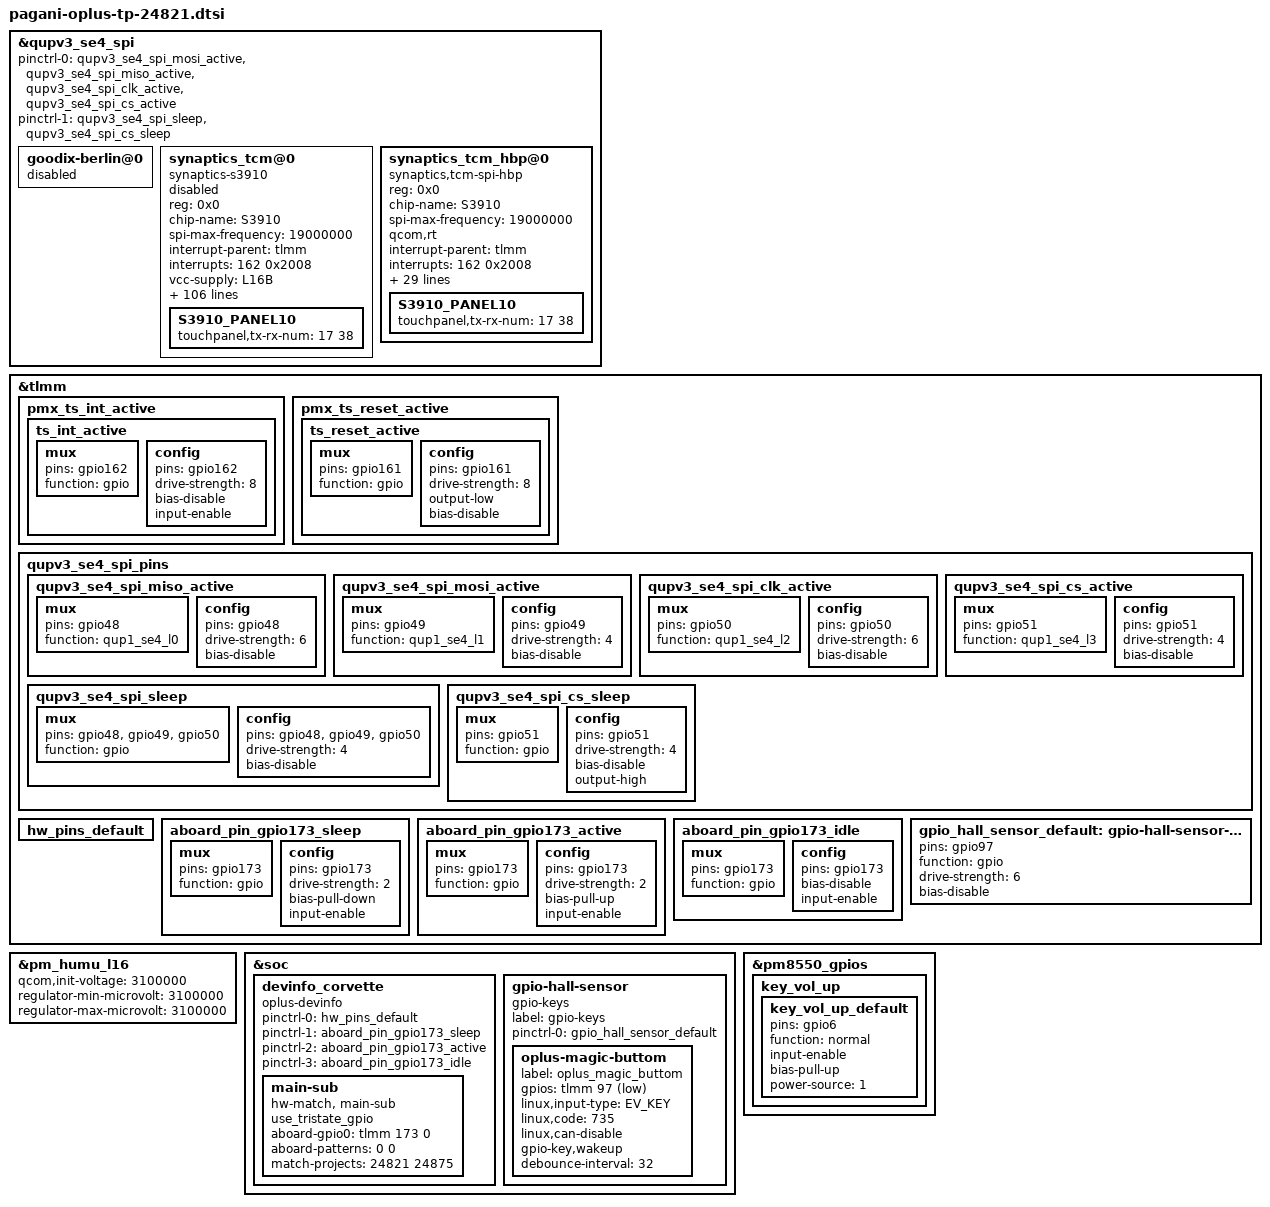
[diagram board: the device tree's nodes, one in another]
&qupv3_se4_spi{
	/delete-property/ pinctrl-0;
	/delete-property/ pinctrl-1;
	pinctrl-0 = <&qupv3_se4_spi_mosi_active>, <&qupv3_se4_spi_miso_active>,
				<&qupv3_se4_spi_clk_active>, <&qupv3_se4_spi_cs_active>;
	pinctrl-1 = <&qupv3_se4_spi_sleep>, <&qupv3_se4_spi_cs_sleep>;
};

&qupv3_se4_spi {
	status = "ok";

	goodix-berlin@0 {
		status = "disabled";
	};

	synaptics_tcm@0{
		compatible = "synaptics-s3910";
		reg = <0x0>;
		chip-name = "S3910";
		status = "disabled";
		spi-max-frequency = <19000000>;

		/* Interrupt && Irq-gpio */
		interrupt-parent = <&tlmm>;
		interrupts = <162 0x2008>;

		/* Power Config */
		//synaptics,avdd-gpio = <&pm8550vs_j_gpios 3 0x1>;
		vcc-supply = <&L16B>;
		vdd-supply = <&L4B>;
		synaptics,vdd-name = "vdd";
		synaptics,avdd-name = "vcc";

		/* Other HW Resource */
		irq-gpio = <&tlmm 162 0x2008>;
		reset-gpio = <&tlmm 161 0x1>;
		pinctrl-names = "default";
		pinctrl-0 = <&ts_int_active &ts_reset_active>;


		touchpanel,max-num-support = <10>;
		touchpanel,tx-rx-num = <17 37>;
		touchpanel,panel-coords = <19456 42240>;
		touchpanel,display-coords = <1216 2640>;
		touchpanel,touchmajor-limit = <128 216>;
		touchpanel,elimination-range = <20 200 200>;
		touchpanel,int-mode = <1>; /*0: interrupt and disable, 1:interrupt and not disable*/
		touchpanel,smooth-level = <0 1 2 4 7 9>;
		touchpanel,smooth-level-charging = <0 2 4 7 8 9>;
		touchpanel,sensitive-level = <0 70 55 40 25 10>;
		touchpanel,single-optimized-time = <8>;
		touchpanel,high-frame-rate-time = <60>;

		vid_len = <2>;
		panel_type = <7>; /*type:3 TM*/
		platform_support_project = <24821>;
		platform_support_project_dir = <24821>;
		platform_support_project_commandline = "default_commandline";

		prevention,curved_screen_V2;
		prevention,grip_disable_level = <6>;
		prevention,updelay_time_ms = <30>;
		prevention,makeup_cnt_weight = <4 1 2 2 2>;
		prevention,large_corner_range = <1380 3400>;
		prevention,large_corner_judge_condition = <500 300 1000 7 7>;
		prevention,trx_reject_condition = <8 7 7>;
		prevention,trx_strict_reject_condition = <8 6 6>;
		prevention,large_judge_time_ms = <500 50 30>;
		prevention,large_exit_condition = <8 8 2>;
		prevention,single_channel_width = <320 320>;
		prevention,normal_tap_condition = <10 350>;
		prevention,long_edge_condition = <179 90 120 80>;
		prevention,long_strict_edge_condition = <160 60>;
		prevention,long_fingerhold_condition = <70 6 4 4>;
		prevention,short_edge_condition = <179 90 120 80>;
		prevention,short_strict_edge_condition = <160 60>;
		prevention,large_strict_exit_condition = <6 6>;
		prevention,top_corner_config = <250 750 1000>;
		prevention,edge_swipe_config = <340 1130>;

		prevention,curved_screen_V4;
		prevention,long_eliminate_point_type = <2 12400 9240 240 27720 300 1>;
		prevention,long_fingerhold_condition2 = <700 2000 0 0>;
		prevention,top_corner_config2 =<3 80 600 1500 0>;
		prevention,hor_long_top_corner_config =<300 2000 0 0>;
		prevention,top_middle_config =<12400 1000 1000 0>;
		prevention,corner_eliminate_point_type =<0 1380 2270 1>;
		prevention,finger_hold_differ_size = <1 0 400 300>;
		prevention,finger_hold_max_rx_exit_distance = <5 350 2300>;
		prevention,max_rx_exit_distance = <1 5 150 350 2000>;
		prevention,dynamic_finger_hold_exit_distance = <1 350 2300 450>;
		prevention,edge_sliding_matched_support = <1 150 3 0>;

		//grip v4.2 reclining mode
		prevention,reclining_mode_support = <1>;
		prevention,long_eliminate_point_type_recli = <2 12400 9240 240 27720 500 1>;
		prevention,finger_hold_differ_size_recli = <1 0 400 400>;
		prevention,finger_hold_max_rx_exit_distance_recli = <5 350 2300>;
		prevention,max_rx_exit_distance_recli = <1 5 100 350 2300>;
		prevention,dynamic_finger_hold_exit_distance_recli = <1 350 2300 450>;
		prevention,edge_sliding_matched_support_recli = <1 150 3 0>;
		prevention,long_edge_condition_recli = <179 90 120 80>;


		/* SW Support Feature Control */
		black_gesture_support;
		sportify_aod_gesture_support;
		pressure_report_support;
		charger_pump_support;
		game_switch_support;
		glove_mode_support;
		smart_gesture_support;
		fw_update_app_support;
		fingerprint_underscreen_support;
		freq_hop_simulate_support;
		report_flow_unlock_support;
		screenoff_fingerprint_info_support;
		irq_need_dev_resume_ok;
		enable_point_auto_change;
		kernel_grip_support;
		//grip_no_driver_support;
		health_monitor_support;
		black_gesture_indep_support;
		snr_read_support;
		palm_to_sleep_support;
		exception_upload_support;
		tp_data_record_support;
		fingerprint_not_report_in_suspend;
		/*
		 *Virtual Key Config:
		 *1:touchpanel,button-type: <virtualkey_type  supportted_button-map>
		 *virtualkey_type:
		 *Type 1: using board_properties
		 *Type 2: using same IC (button zone&& touch zone are seprate)
		 *Type 3: using diffrent IC (button zone&& touch zone are seprate)
		 *Type 4: No need of virtual key process
		 *supportted_button-map:select|menu|home|back
		 *
		 *2:touchpanel,button-map
		 *type (X1,Y1)(X2,Y2)(X3,Y3)(Width_X,Hight_Y)--Only when button-type is 0
		 */
		touchpanel,button-type = <4>;
		touchpanel.button-TRx = <0 0>;

		S3910_PANEL10 {
			touchpanel,tx-rx-num = <17 38>;
		};
	};

	synaptics_tcm_hbp@0{
		compatible = "synaptics,tcm-spi-hbp";
		reg = <0x0>;
		chip-name = "S3910";
		status = "okay";
		spi-max-frequency = <19000000>;
		qcom,rt;

		/* Interrupt && Irq-gpio */
		interrupt-parent = <&tlmm>;
		interrupts = <162 0x2008>;

		/* Power Config */
		//synaptics,avdd-gpio = <&pm8550vs_j_gpios 3 0x1>;
		vcc-supply = <&L16B>;
		vdd-supply = <&L4B>;
		synaptics,vdd-name = "vdd";
		synaptics,avdd-name = "vcc";

		/* Other HW Resource */
		synaptics,irq-gpio = <&tlmm 162 0x2008>;
		synaptics,reset-gpio = <&tlmm 161 0x1>;
		pinctrl-names = "default";
		pinctrl-0 = <&ts_int_active &ts_reset_active>;

		touchpanel,panel-coords = <19456 42240>;
		touchpanel,tx-rx-num = <17 37>;
		touchpanel,tp_ic_type = <2>;
		panel_type = <10 7>;
		// type of tp_dev ,TP-SAMSUNG = 8;
		firmware_name = "AA590";
		platform_support_project = <24821 24875>;
		platform_support_project_dir = <24821 24821>;
		platform_support_project_commandline = "mdss_dsi_panel_AA590_P_3_A0020_dsc_cmd", "mdss_dsi_panel_AA594_P_7_A0020_dsc_cmd";

		synaptics,power-on-state = <1>;
		synaptics,power-delay-ms = <200>;
		synaptics,irq-on-state = <0>;
		synaptics,reset-on-state = <0>;
		synaptics,reset-active-ms = <10>;
		synaptics,reset-delay-ms = <80>;
		synaptics,spi-mode = <0>;
		synaptics,spi-byte-delay-us = <0>;
		synaptics,spi-block-delay-us = <0>;

		/* SW Support Feature Control */
		tp_data_record_support;
		stats_upload_support;
		fingerprint_not_report_in_suspend;
		S3910_PANEL10 {
			touchpanel,tx-rx-num = <17 38>;
		};
	};
};
/*
&pm8550vs_j_gpios {
	ts_avdd_active: ts_avdd_active {
		pins = "gpio3";
		function = "normal";
		input-disable;
		output-enable;
		output-low;
		power-source = <1>;
	};
};
*/
&tlmm {
/*	gpio_wakeup: gpio_wakeup {
		compatible = "gpio_wakeup";
		gpio_table = <8 11 15 20 23 56 57 59 63 65 66 77 81 84 153 155 171 172 177 188 195>;
	};
*/
	pmx_ts_int_active {
		ts_int_active: ts_int_active {
			mux {
				pins = "gpio162";
				function = "gpio";
			};

			config {
				pins = "gpio162";
				drive-strength = <8>;
				bias-disable;
				input-enable;
			};
		};
	};

	pmx_ts_reset_active {
		ts_reset_active: ts_reset_active {
			mux {
				pins = "gpio161";
				function = "gpio";
			};

			config {
				pins = "gpio161";
				drive-strength = <8>;
				output-low;
				bias-disable;
			};
		};
	};

	qupv3_se4_spi_pins: qupv3_se4_spi_pins {
		qupv3_se4_spi_miso_active: qupv3_se4_spi_miso_active {
			mux {
				pins = "gpio48";
				function = "qup1_se4_l0";
			};

			config {
				pins = "gpio48";
				drive-strength = <6>;
				bias-disable;
			};
		};

		qupv3_se4_spi_mosi_active: qupv3_se4_spi_mosi_active {
			mux {
				pins = "gpio49";
				function = "qup1_se4_l1";
			};

			config {
				pins = "gpio49";
				drive-strength = <4>;
				bias-disable;
			};
		};

		qupv3_se4_spi_clk_active: qupv3_se4_spi_clk_active {
			mux {
				pins = "gpio50";
				function = "qup1_se4_l2";
			};

			config {
				pins = "gpio50";
				drive-strength = <6>;
				bias-disable;
			};
		};

		qupv3_se4_spi_cs_active: qupv3_se4_spi_cs_active {
			mux {
				pins = "gpio51";
				function = "qup1_se4_l3";
			};

			config {
				pins = "gpio51";
				drive-strength = <4>;
				bias-disable;
			};
		};

		qupv3_se4_spi_sleep: qupv3_se4_spi_sleep {
			mux {
				pins = "gpio48", "gpio49",
						"gpio50";
				function = "gpio";
			};

			config {
				pins = "gpio48", "gpio49",
						"gpio50";
				drive-strength = <4>;
				bias-disable;
			};
		};

		qupv3_se4_spi_cs_sleep: qupv3_se4_spi_cs_sleep {
			mux {
				pins = "gpio51";
				function = "gpio";
			};

			config {
				pins = "gpio51";
				drive-strength = <4>;
				bias-disable;
				output-high;
			};
		};
	};

};

&pm_humu_l16 {
	qcom,init-voltage = <3100000>;
	regulator-min-microvolt = <3100000>;
	regulator-max-microvolt = <3100000>;
};

&soc {
	devinfo_corvette {
		compatible = "oplus-devinfo";
		pinctrl-names = "default", "sleep", "active", "idle";
		pinctrl-0 = <&hw_pins_default>;
		pinctrl-1 = <&aboard_pin_gpio173_sleep>;
		pinctrl-2 = <&aboard_pin_gpio173_active>;
		pinctrl-3 = <&aboard_pin_gpio173_idle>;

		main-sub {
			use_tristate_gpio;
			compatible = "hw-match, main-sub";
			aboard-gpio0 = <&tlmm 173 0>;
			aboard-patterns = <0 0>;	/*0[high-resistance] 1[pull-down] 2[pull-up]*/
			/*main board*/
			match-projects = <24821 24875>;
		};
	};
};

&tlmm {
	hw_pins_default:hw_pins_default {
	};
	aboard_pin_gpio173_sleep:aboard_pin_gpio173_sleep {
		mux {
			pins = "gpio173";
			function = "gpio";
		};
		config {
			pins = "gpio173";
			drive-strength = <2>;
			bias-pull-down;
			input-enable;
		};
	};

	aboard_pin_gpio173_active:aboard_pin_gpio173_active {
		mux {
			pins = "gpio173";
			function = "gpio";
		};
		config {
			pins = "gpio173";
			drive-strength = <2>;
			bias-pull-up;
			input-enable;
		};
	};

	aboard_pin_gpio173_idle:aboard_pin_gpio173_idle {
		mux {
			pins = "gpio173";
			function = "gpio";
		};
		config {
			pins = "gpio173";
			bias-disable;
			input-enable;
		};
	};
};

&pm8550_gpios {
	key_vol_up {
		key_vol_up_default: key_vol_up_default {
			pins = "gpio6";
			function = "normal";
			input-enable;
			bias-pull-up;
			power-source = <1>;
		};
	};
};

&soc {
	gpio-hall-sensor {
		compatible = "gpio-keys";
		label = "gpio-keys";
		status = "okay";
		pinctrl-0 = <&gpio_hall_sensor_default>;
		pinctrl-names = "default";
		oplus-magic-buttom {
			label = "oplus_magic_buttom";
			gpios = <&tlmm 97 GPIO_ACTIVE_LOW>;
			linux,input-type = <EV_KEY>;
			linux,code = <735>; /* means: BTN_TRIGGER_HAPPY32 */
			linux,can-disable;
			gpio-key,wakeup;
			debounce-interval = <32>; /* standard debounce time 32ms */
		};
	};
};

&tlmm {
	gpio_hall_sensor_default: gpio-hall-sensor-default-state {
		pins = "gpio97";
		function = "gpio";
		drive-strength = <6>;
		bias-disable;
	};
};
